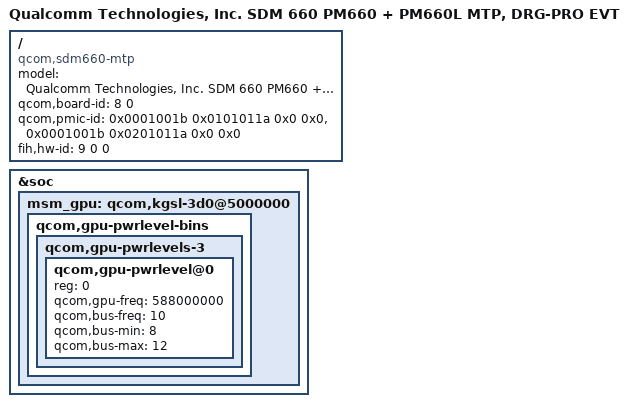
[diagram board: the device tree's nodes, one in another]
/* Copyright (c) 2017, The Linux Foundation. All rights reserved.
 *
 * This program is free software; you can redistribute it and/or modify
 * it under the terms of the GNU General Public License version 2 and
 * only version 2 as published by the Free Software Foundation.
 *
 * This program is distributed in the hope that it will be useful,
 * but WITHOUT ANY WARRANTY; without even the implied warranty of
 * MERCHANTABILITY or FITNESS FOR A PARTICULAR PURPOSE.  See the
 * GNU General Public License for more details.
 */


/dts-v1/;

#include "sdm660.dtsi"
#include "sdm660-mtp.dtsi"
//FIXED ME: Audio Codec
#include "sdm660-internal-codec-drg-ti.dtsi"
#include "fih/nokia/drg-DVT1.5-636.dtsi"

/ {
	model = "Qualcomm Technologies, Inc. SDM 660 PM660 + PM660L MTP, DRG-PRO EVT";
	compatible = "qcom,sdm660-mtp", "qcom,sdm660", "qcom,mtp";
	qcom,board-id = <8 0>;
	qcom,pmic-id = <0x0001001b 0x0101011a 0x0 0x0>,
			<0x0001001b 0x0201011a 0x0 0x0>;
	fih,hw-id = <9 0 0>;
};
&soc {
	msm_gpu: qcom,kgsl-3d0@5000000 {
		qcom,gpu-pwrlevel-bins {
			qcom,gpu-pwrlevels-3 {
				qcom,gpu-pwrlevel@0 {
					reg = <0>;
					qcom,gpu-freq = <588000000>;
					qcom,bus-freq = <10>;
					qcom,bus-min = <8>;
					qcom,bus-max = <12>;
				};
			};
		};
	};
};

